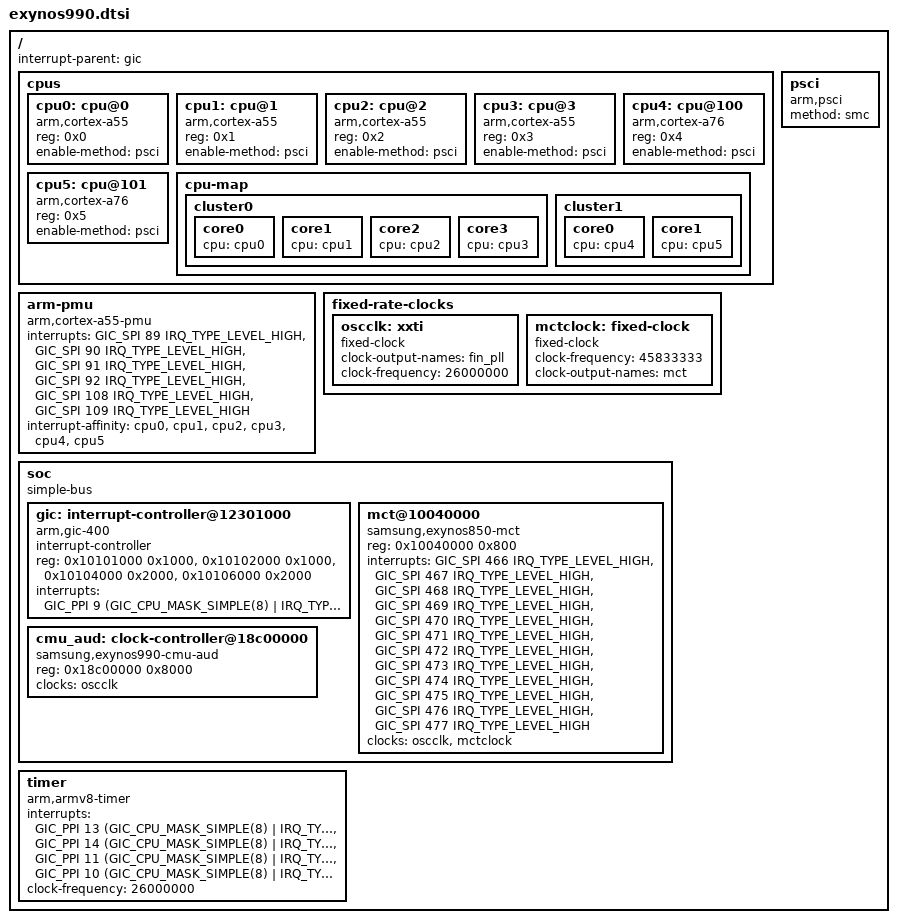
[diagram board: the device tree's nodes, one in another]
// SPDX-License-Identifier: GPL-2.0-only
/*
 * Copyright (c) 2024, Igor Belwon <thenxguy0@gmail.com>
 */

#include <dt-bindings/interrupt-controller/arm-gic.h>

/ {
	#address-cells = <2>;
	#size-cells = <2>;
	interrupt-parent = <&gic>;

	cpus {
		#address-cells = <1>;
		#size-cells = <0>;

		cpu0: cpu@0 {
			device_type = "cpu";
			compatible = "arm,cortex-a55";
			reg = <0x0>;
			enable-method = "psci";
		};

		cpu1: cpu@1 {
			device_type = "cpu";
			compatible = "arm,cortex-a55";
			reg = <0x1>;
			enable-method = "psci";
		};

		cpu2: cpu@2 {
			device_type = "cpu";
			compatible = "arm,cortex-a55";
			reg = <0x2>;
			enable-method = "psci";
		};

		cpu3: cpu@3 {
			device_type = "cpu";
			compatible = "arm,cortex-a55";
			reg = <0x3>;
			enable-method = "psci";
		};

		cpu4: cpu@100 {
			device_type = "cpu";
			compatible = "arm,cortex-a76";
			reg = <0x4>;
			enable-method = "psci";
		};

		cpu5: cpu@101 {
			device_type = "cpu";
			compatible = "arm,cortex-a76";
			reg = <0x5>;
			enable-method = "psci";
		};

		cpu-map {
			cluster0 {
				core0 {
					cpu = <&cpu0>;
				};

				core1 {
					cpu = <&cpu1>;
				};

				core2 {
					cpu = <&cpu2>;
				};

				core3 {
					cpu = <&cpu3>;
				};
			};

			cluster1 {
				core0 {
					cpu = <&cpu4>;
				};

				core1 {
					cpu = <&cpu5>;
				};
			};
		};
    };

	arm-pmu {
		compatible = "arm,cortex-a55-pmu";
		interrupts = <GIC_SPI 89 IRQ_TYPE_LEVEL_HIGH>,
			     <GIC_SPI 90 IRQ_TYPE_LEVEL_HIGH>,
			     <GIC_SPI 91 IRQ_TYPE_LEVEL_HIGH>,
			     <GIC_SPI 92 IRQ_TYPE_LEVEL_HIGH>,
			     <GIC_SPI 108 IRQ_TYPE_LEVEL_HIGH>,
			     <GIC_SPI 109 IRQ_TYPE_LEVEL_HIGH>;
		interrupt-affinity = <&cpu0>, <&cpu1>, <&cpu2>, <&cpu3>,
				     <&cpu4>, <&cpu5>;
	};

	psci {
		compatible = "arm,psci";
		method = "smc";
	};

	fixed-rate-clocks {
	  	oscclk: xxti {
			compatible = "fixed-clock";
			clock-output-names = "fin_pll";
			clock-frequency = <26000000>;
			#clock-cells = <0>;
  		};

		mctclock: fixed-clock {
			compatible = "fixed-clock";
			#clock-cells = <0>;
			clock-frequency = <45833333>;
			clock-output-names = "mct";
		};
	};

	soc: soc {
		compatible = "simple-bus";
		#address-cells = <1>;
		#size-cells = <1>;
		ranges = <0 0 0 0xffffffff>;

		gic: interrupt-controller@12301000 {
			compatible = "arm,gic-400";
			#interrupt-cells = <3>;
			#address-cells = <0>;
			interrupt-controller;
			reg = <0x10101000 0x1000>,
			      <0x10102000 0x1000>,
			      <0x10104000 0x2000>,
			      <0x10106000 0x2000>;
			interrupts = <GIC_PPI 9 (GIC_CPU_MASK_SIMPLE(8) |
						 IRQ_TYPE_LEVEL_HIGH)>;
		};

		mct@10040000 {
			compatible = "samsung,exynos850-mct";
			reg = <0x10040000 0x800>;
			interrupts = <GIC_SPI 466 IRQ_TYPE_LEVEL_HIGH>,
					<GIC_SPI 467 IRQ_TYPE_LEVEL_HIGH>,
					<GIC_SPI 468 IRQ_TYPE_LEVEL_HIGH>,
					<GIC_SPI 469 IRQ_TYPE_LEVEL_HIGH>,
					<GIC_SPI 470 IRQ_TYPE_LEVEL_HIGH>,
					<GIC_SPI 471 IRQ_TYPE_LEVEL_HIGH>,
					<GIC_SPI 472 IRQ_TYPE_LEVEL_HIGH>,
					<GIC_SPI 473 IRQ_TYPE_LEVEL_HIGH>,
					<GIC_SPI 474 IRQ_TYPE_LEVEL_HIGH>,
					<GIC_SPI 475 IRQ_TYPE_LEVEL_HIGH>,
					<GIC_SPI 476 IRQ_TYPE_LEVEL_HIGH>,
					<GIC_SPI 477 IRQ_TYPE_LEVEL_HIGH>;
			clocks = <&oscclk>, <&mctclock>;
			clock-names = "fin_pll", "mct";
		};

		cmu_aud: clock-controller@18c00000 {
			compatible = "samsung,exynos990-cmu-aud";
			reg = <0x18c00000 0x8000>;
			#clock-cells = <1>;

			clocks = <&oscclk>;
			clock-names = "oscclk";
		};

	};

	timer {
		compatible = "arm,armv8-timer";
		interrupts =
					<GIC_PPI 13 (GIC_CPU_MASK_SIMPLE(8) | IRQ_TYPE_LEVEL_LOW)>,
					<GIC_PPI 14 (GIC_CPU_MASK_SIMPLE(8) | IRQ_TYPE_LEVEL_LOW)>,
					<GIC_PPI 11 (GIC_CPU_MASK_SIMPLE(8) | IRQ_TYPE_LEVEL_LOW)>,
					<GIC_PPI 10 (GIC_CPU_MASK_SIMPLE(8) | IRQ_TYPE_LEVEL_LOW)>;
		clock-frequency = <26000000>;
	};
};
